# R7FA6T3BB register map
Vendor: Renesas Electronics Corporation; Series: RA6; File version: 1.20.00
CPU: CM33 r0p4, little endian, MPU, FPU, VTOR, 4 interrupt priority bits, 96 interrupts
Registers are 32-bit, read-write, reset 0x0 unless marked. A register's access mark holds for its fields unless they carry their own. Offsets are from the block's base; [hi:lo] are bit positions; {n}, {i} and the like mark numbered series; 'fields as' and 'values as' point back to an identical list.

## USBFS — USB 2.0 Full-Speed Module
Base 0x40090000
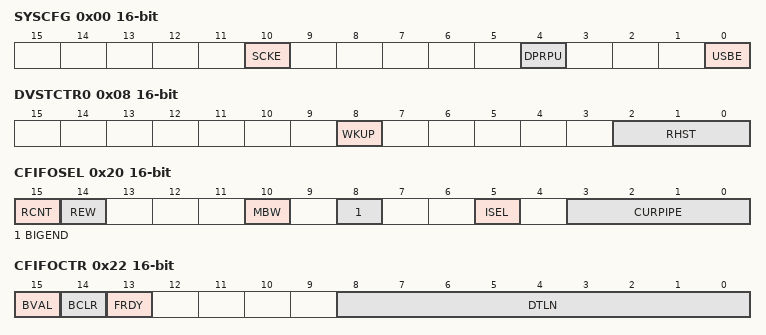
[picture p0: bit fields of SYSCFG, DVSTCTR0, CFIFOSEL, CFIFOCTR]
0x00 SYSCFG 16-bit — System Configuration Control Register
  [10] SCKE — USB Clock Enable
    0=Stop clock supply to the USBFS; 1=Enable clock supply to the USBFS
  [4] DPRPU — D+ Line Resistor Control
    0=Disable line pull-up; 1=Enable line pull-up
  [0] USBE — USBFS Operation Enable
    0=Disable; 1=Enable
0x04 SYSSTS0 16-bit ro — System Configuration Status Register 0
  [1:0] LNST — USB Data Line Status Monitor
0x08 DVSTCTR0 16-bit — Device State Control Register 0
  [8] WKUP — Wakeup Output
    0=Do not output remote wakeup signal; 1=Output remote wakeup signal
  [2:0] RHST ro — USB Bus Reset Status
    0=Communication speed indeterminate; 1=USB bus reset in progress; 2=USB bus reset in progress or full-speed connection; other=Others (Setting prohibited)
0x14 CFIFO 16-bit — CFIFO Port Register
  [15:0] FIFOPORT
0x14 CFIFOL 8-bit (alternate view of CFIFO) — CFIFO Port Register
  [7:0] FIFOPORT
0x20 CFIFOSEL 16-bit — CFIFO Port Select Register
  [15] RCNT — Read Count Mode
    0=The DTLN[8:0] bits (CFIFOCTR.DTLN[8:0]) are cleared when all receive data is read from the CFIFO. In double buffer mode, the DTLN[8:0] value is cleared when all data is read from only a single plane.; 1=The DTLN[8:0] bits are decremented each time the receive data is read from the CFIFO
  [14] REW wo — Buffer Pointer Rewind
    0=Do not rewind buffer pointer; 1=Rewind buffer pointer
  [10] MBW — CFIFO Port Access Bit Width
    0=8-bit width; 1=16-bit width
  [8] BIGEND — CFIFO Port Endian Control
    0=Little endian; 1=Big endian
  [5] ISEL — CFIFO Port Access Direction When DCP Is Selected
    0=Select reading from the FIFO buffer; 1=Select writing to the FIFO buffer
  [3:0] CURPIPE — CFIFO Port Access Pipe Specification
    0=Default Control Pipe; {v}=Pipe {v} (v=4..7); other=Others (Setting prohibited)
0x22 CFIFOCTR 16-bit — CFIFO Port Control Register
  [15] BVAL — Buffer Memory Valid Flag
    0=Invalid (writing 0 has no effect); 1=Writing ended
  [14] BCLR wo — CPU Buffer Clear
    0=No operation; 1=Clear FIFO buffer on the CPU side
  [13] FRDY ro — FIFO Port Ready
    0=FIFO port access disabled; 1=FIFO port access enabled
  [8:0] DTLN ro — Receive Data Length
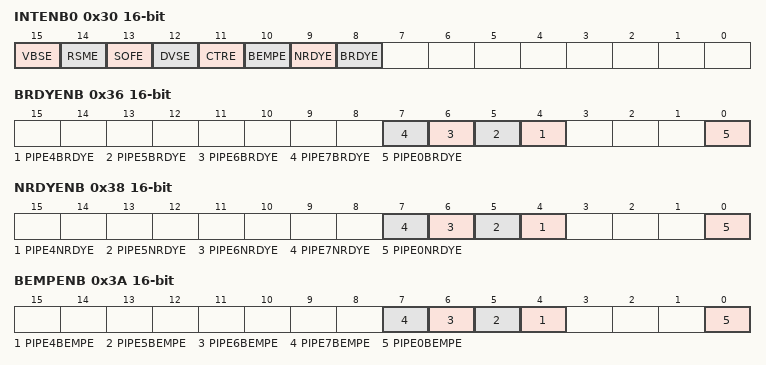
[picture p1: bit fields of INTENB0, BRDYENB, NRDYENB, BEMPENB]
0x30 INTENB0 16-bit — Interrupt Enable Register 0
  [all] fields
    0=Disable interrupt request; 1=Enable interrupt request
  [15] VBSE — VBUS Interrupt Enable
  [14] RSME — Resume Interrupt Enable
  [13] SOFE — Frame Number Update Interrupt Enable
  [12] DVSE — Device State Transition Interrupt Enable
  [11] CTRE — Control Transfer Stage Transition Interrupt Enable
  [10] BEMPE — Buffer Empty Interrupt Enable
  [9] NRDYE — Buffer Not Ready Response Interrupt Enable
  [8] BRDYE — Buffer Ready Interrupt Enable
0x36 BRDYENB 16-bit — BRDY Interrupt Enable Register
  [all] fields
    0=Disable interrupt request; 1=Enable interrupt request
  [n] PIPE{n}BRDYE (n=4..7) — BRDY Interrupt Enable for Pipe {n}
  [0] PIPE0BRDYE — BRDY Interrupt Enable for Pipe 0
0x38 NRDYENB 16-bit — NRDY Interrupt Enable Register
  [all] fields
    0=Disable interrupt request; 1=Enable interrupt request
  [n] PIPE{n}NRDYE (n=4..7) — NRDY Interrupt Enable for Pipe {n}
  [0] PIPE0NRDYE — NRDY Interrupt Enable for Pipe 0
0x3A BEMPENB 16-bit — BEMP Interrupt Enable Register
  [all] fields
    0=Disable interrupt request; 1=Enable interrupt request
  [n] PIPE{n}BEMPE (n=4..7) — BEMP Interrupt Enable for Pipe {n}
  [0] PIPE0BEMPE — BEMP Interrupt Enable for Pipe 0
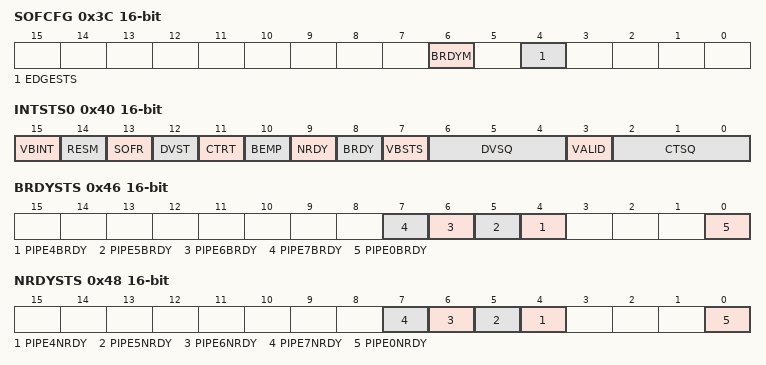
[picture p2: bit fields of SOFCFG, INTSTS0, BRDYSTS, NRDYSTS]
0x3C SOFCFG 16-bit — SOF Output Configuration Register
  [6] BRDYM — BRDY Interrupt Status Clear Timing
    0=Clear BRDY flag by software; 1=Clear BRDY flag by the USBFS through a data read from the FIFO buffer or data write to the FIFO buffer
  [4] EDGESTS ro — Edge Interrupt Output Status Monitor
0x40 INTSTS0 16-bit (reset mask 0xEF6F) — Interrupt Status Register 0
  [15] VBINT — VBUS Interrupt Status
    0=No VBUS interrupt occurred; 1=VBUS interrupt occurred
  [14] RESM — Resume Interrupt Status
    0=No resume interrupt occurred; 1=Resume interrupt occurred
  [13] SOFR — Frame Number Refresh Interrupt Status
    0=No SOF interrupt occurred; 1=SOF interrupt occurred
  [12] DVST — Device State Transition Interrupt Status
    0=No device state transition interrupt occurred; 1=Device state transition interrupt occurred
  [11] CTRT — Control Transfer Stage Transition Interrupt Status
    0=No control transfer stage transition interrupt occurred; 1=Control transfer stage transition interrupt occurred
  [10] BEMP ro — Buffer Empty Interrupt Status
    0=No BEMP interrupt occurred; 1=BEMP interrupt occurred
  [9] NRDY ro — Buffer Not Ready Interrupt Status
    0=No NRDY interrupt occurred; 1=NRDY interrupt occurred
  [8] BRDY ro — Buffer Ready Interrupt Status
    0=No BRDY interrupt occurred; 1=BRDY interrupt occurred
  [7] VBSTS ro — VBUS Input Status
    0=USB_VBUS pin is low; 1=USB_VBUS pin is high
  [6:4] DVSQ ro — Device State
    0=Powered state; 1=Default state; 2=Address state; 3=Configured state; other=Others (Suspend state)
  [3] VALID — USB Request Reception
    0=Setup packet not received; 1=Setup packet received
  [2:0] CTSQ ro — Control Transfer Stage
    0=Idle or setup stage; 1=Control read data stage; 2=Control read status stage; 3=Control write data stage; 4=Control write status stage; 5=Control write (no data) status stage; 6=Control transfer sequence error
0x46 BRDYSTS 16-bit — BRDY Interrupt Status Register
  [all] fields
    0=No BRDY interrupt occurred; 1=BRDY interrupt occurred
  [n] PIPE{n}BRDY (n=4..7) — BRDY Interrupt Status for Pipe {n}
  [0] PIPE0BRDY — BRDY Interrupt Status for Pipe 0
0x48 NRDYSTS 16-bit — NRDY Interrupt Status Register
  [all] fields
    0=No NRDY interrupt occurred; 1=NRDY interrupt occurred
  [n] PIPE{n}NRDY (n=4..7) — NRDY Interrupt Status for Pipe {n}
  [0] PIPE0NRDY — NRDY Interrupt Status for Pipe 0
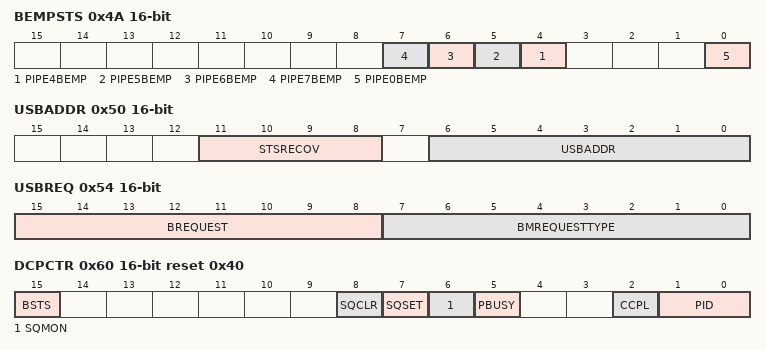
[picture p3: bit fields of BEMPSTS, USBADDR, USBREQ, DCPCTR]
0x4A BEMPSTS 16-bit — BEMP Interrupt Status Register
  [all] fields
    0=No BEMP interrupt occurred; 1=BEMP interrupt occurred
  [n] PIPE{n}BEMP (n=4..7) — BEMP Interrupt Status for Pipe {n}
  [0] PIPE0BEMP — BEMP Interrupt Status for Pipe 0
0x4C FRMNUM 16-bit ro — Frame Number Register
  [10:0] FRNM — Frame Number
0x4E DVCHGR 16-bit — Device State Change Register
  [15] DVCHG — Device State Change
    0=Disable writes to the USBADDR.STSRECOV[3:0] and USBADDR.USBADDR[6:0] bits; 1=Enable writes to the USBADDR.STSRECOV[3:0] and USBADDR.USBADDR[6:0] bits
0x50 USBADDR 16-bit — USB Address Register
  [11:8] STSRECOV — Status Recovery
    9=Return to the full-speed state (bits DVSTCTR0.RHST[2:0] = 010b), bits INTSTS0.DVSQ[2:0] = 001b (default state); 10=Return to the full-speed state (bits DVSTCTR0.RHST[2:0] = 010b), bits INTSTS0.DVSQ[2:0] = 010b (address state); 11=Return to the full-speed state (bits DVSTCTR0.RHST[2:0] = 010b), bits INTSTS0.DVSQ[2:0] = 011b (configured state); other=Others (Setting prohibited)
  [6:0] USBADDR — USB Address
0x54 USBREQ 16-bit ro — USB Request Type Register
  [15:8] BREQUEST — Request
  [7:0] BMREQUESTTYPE — Request Type
0x56 USBVAL 16-bit ro — USB Request Value Register
  [15:0] WVALUE — Value
0x58 USBINDX 16-bit ro — USB Request Index Register
  [15:0] WINDEX — Index
0x5A USBLENG 16-bit ro — USB Request Length Register
  [15:0] WLENTUH — Length
0x5C DCPCFG 16-bit — DCP Configuration Register
  [7] SHTNAK — Pipe Disabled at End of Transfer
    0=Keep pipe open after transfer ends; 1=Disable pipe after transfer ends
0x5E DCPMAXP 16-bit reset 0x40 — DCP Maximum Packet Size Register
  [6:0] MXPS — Maximum Packet Size
0x60 DCPCTR 16-bit reset 0x40 — DCP Control Register
  [15] BSTS ro — Buffer Status
    0=Buffer access disabled; 1=Buffer access enabled
  [8] SQCLR — Sequence Toggle Bit Clear
    0=Invalid (writing 0 has no effect); 1=Clear the expected value for the next transaction to DATA0
  [7] SQSET — Sequence Toggle Bit Set
    0=Invalid (writing 0 has no effect); 1=Set the expected value for the next transaction to DATA1
  [6] SQMON ro — Sequence Toggle Bit Monitor
    0=DATA0; 1=DATA1
  [5] PBUSY ro — Pipe Busy
    0=DCP not used for the USB bus; 1=DCP in use for the USB bus
  [2] CCPL — Control Transfer End Enable
    0=Disable control transfer completion; 1=Enable control transfer completion
  [1:0] PID — Response PID
    0=NAK response; 1=BUF response (depends on the buffer state); 2=STALL response; 3=STALL response
0x64 PIPESEL 16-bit — Pipe Window Select Register
  [3:0] PIPESEL — Pipe Window Select
    0=No pipe selected; {v}=Pipe {v} (v=4..7); other=Others (Setting prohibited)
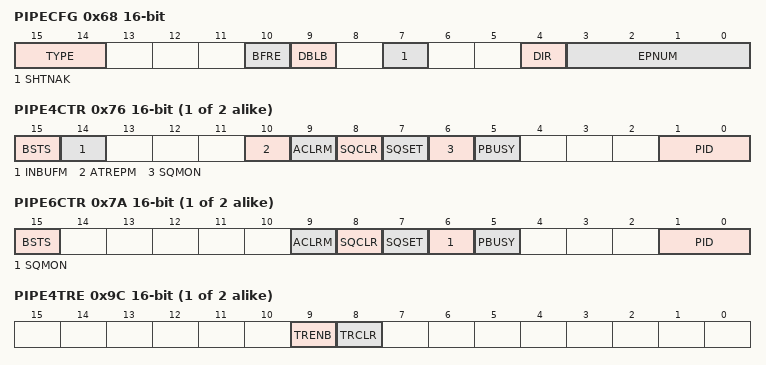
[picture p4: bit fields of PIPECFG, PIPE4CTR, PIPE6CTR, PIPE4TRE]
0x68 PIPECFG 16-bit — Pipe Configuration Register
  [15:14] TYPE — Transfer Type
    0=Pipe not used; 1=Pipes 4 and 5: Bulk transfer Pipes 6 and 7: Setting prohibited; 2=Pipes 4 and 5: Setting prohibited Pipes 6 and 7: Interrupt transfer; 3=Pipes 4 and 5: Setting prohibited Pipes 6 and 7: Setting prohibited
  [10] BFRE — BRDY Interrupt Operation Specification
    0=Generate BRDY interrupt on transmitting or receiving data; 1=Generate BRDY interrupt on completion of reading data
  [9] DBLB — Double Buffer Mode
    0=Single buffer; 1=Double buffer
  [7] SHTNAK — Pipe Disabled at End of Transfer
    0=Continue pipe operation after transfer ends; 1=Disable pipe after transfer ends
  [4] DIR — Transfer Direction
    0=Receiving direction; 1=Transmitting direction
  [3:0] EPNUM — Endpoint Number
0x6C PIPEMAXP 16-bit (reset mask 0xFFBF) — Pipe Maximum Packet Size Register
  [8:0] MXPS — Maximum Packet Size
{0x6E+2i} PIPE{i}CTR (i=4..5) 16-bit — PIPE{i} Control Registers
  [15] BSTS ro — Buffer Status
    0=Buffer access by the CPU disabled; 1=Buffer access by the CPU enabled
  [14] INBUFM ro — Transmit Buffer Monitor
    0=No data to be transmitted is in the FIFO buffer; 1=Data to be transmitted is in the FIFO buffer
  [10] ATREPM — Auto Response Mode
    0=Disable auto response mode; 1=Enable auto response mode
  [9] ACLRM — Auto Buffer Clear Mode
    0=Disable; 1=Enable (initialize all buffers)
  [8] SQCLR — Sequence Toggle Bit Clear
    values as DCPCTR.SQCLR
  [7] SQSET — Sequence Toggle Bit Set
    values as DCPCTR.SQSET
  [6] SQMON ro — Sequence Toggle Bit Confirmation
    0=DATA0; 1=DATA1
  [5] PBUSY ro — Pipe Busy
    0=Pipe n not in use for the transaction; 1=Pipe n in use for the transaction
  [1:0] PID — Response PID
    0=NAK response; 1=BUF response (depends buffer state); 2=STALL response; 3=STALL response
{0x6E+2i} PIPE{i}CTR (i=6..7) 16-bit — PIPE{i} Control Registers
  [15] BSTS ro — Buffer Status
    0=Buffer access disabled; 1=Buffer access enabled
  [9] ACLRM — Auto Buffer Clear Mode
    0=Disable; 1=Enable (all buffers initialized)
  [8] SQCLR wo — Sequence Toggle Bit Clear
    values as DCPCTR.SQCLR
  [7] SQSET wo — Sequence Toggle Bit Set
    0=Invalid (writing 0 has no effect); 1=Set the expected value for the next transaction to DATA0
  [6] SQMON ro — Sequence Toggle Bit Confirmation
    0=DATA0; 1=DATA1
  [5] PBUSY ro — Pipe Busy
    values as PIPE4CTR.PBUSY
  [1:0] PID — Response PID
    values as PIPE4CTR.PID
{0x8C+4i} PIPE{i}TRE (i=4..5) 16-bit — PIPE{i} Transaction Counter Enable Register
  [9] TRENB — Transaction Counter Enable
    0=Disable transaction counter; 1=Enable transaction counter
  [8] TRCLR — Transaction Counter Clear
    0=Invalid (writing 0 has no effect); 1=Clear counter value
{0x8E+4i} PIPE{i}TRN (i=4..5) 16-bit — PIPE{i} Transaction Counter Register
  [15:0] TRNCNT — Transaction Counter
0xF4 PHYSECTRL — PHY Single-ended Receiver Control Register
  [4] CNEN — Single-ended Receiver Enable
    0=Single-ended receiver operation is disabled; 1=Single-ended receiver operation is enabled
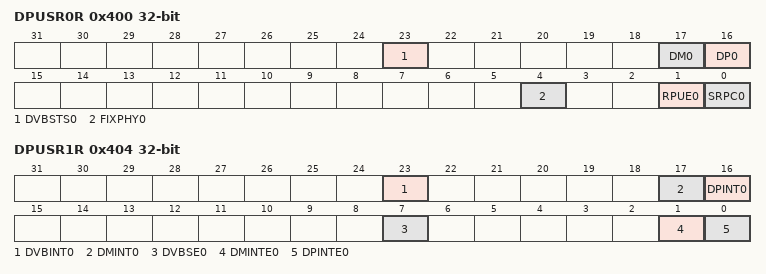
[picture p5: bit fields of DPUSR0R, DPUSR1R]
0x400 DPUSR0R (reset mask 0xFF4CFFFF) — Deep Software Standby USB Transceiver Control/Pin Monitor Register
  [23] DVBSTS0 ro — USB VBUS Input
  [17] DM0 ro — USB D- Input
  [16] DP0 ro — USB D+ Input
  [4] FIXPHY0 — USB Transceiver Output Fix
    0=Fix outputs in Normal mode and on return from Deep Software Standby mode; 1=Fix outputs on transition to Deep Software Standby mode
  [1] RPUE0 — DP Pull-Up Resistor Control
    0=Disable DP pull-up resistor; 1=Enable DP pull-up resistor
  [0] SRPC0 — USB Single-ended Receiver Control
    0=Disable input through DP and DM inputs; 1=Enable input through DP and DM inputs
0x404 DPUSR1R — Deep Software Standby USB Suspend/Resume Interrupt Register
  [23] DVBINT0 ro — USB VBUS Interrupt Source Recovery
    0=System has not recovered from Deep Software Standby mode; 1=System recovered from Deep Software Standby mode because of VBUS input
  [17] DMINT0 ro — USB DM Interrupt Source Recovery
    0=System has not recovered from Deep Software Standby mode; 1=System recovered from Deep Software Standby mode because of DM input
  [16] DPINT0 ro — USB DP Interrupt Source Recovery
    0=System has not recovered from Deep Software Standby mode; 1=System recovered from Deep Software Standby mode because of DP
  [7] DVBSE0 — USB VBUS Interrupt Enable/Clear
    0=Disable recovery from Deep Software Standby mode by VBUS input; 1=Enable recovery from Deep Software Standby mode by VBUS input
  [1] DMINTE0 — USB DM Interrupt Enable/Clear
    0=Disable recovery from Deep Software Standby mode by DM input; 1=Enable recovery from Deep Software Standby mode by DM input
  [0] DPINTE0 — USB DP Interrupt Enable/Clear
    0=Disable recovery from Deep Software Standby mode by DP input; 1=Enable recovery from Deep Software Standby mode by DP input
